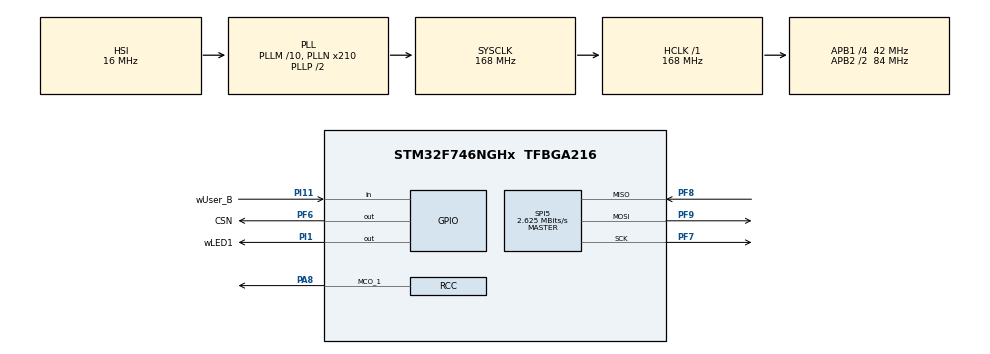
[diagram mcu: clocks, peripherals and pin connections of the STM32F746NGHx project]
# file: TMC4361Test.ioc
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Dma.Request0=SPI5_RX
Dma.Request1=SPI5_TX
Dma.SPI5_RX.0.Direction=DMA_PERIPH_TO_MEMORY
Dma.SPI5_RX.0.FIFOMode=DMA_FIFOMODE_DISABLE
Dma.SPI5_RX.0.Instance=DMA2_Stream3
Dma.SPI5_RX.0.MemDataAlignment=DMA_MDATAALIGN_BYTE
Dma.SPI5_RX.0.MemInc=DMA_MINC_ENABLE
Dma.SPI5_RX.0.Mode=DMA_CIRCULAR
Dma.SPI5_RX.0.PeriphDataAlignment=DMA_PDATAALIGN_BYTE
Dma.SPI5_RX.0.PeriphInc=DMA_PINC_DISABLE
Dma.SPI5_RX.0.Priority=DMA_PRIORITY_MEDIUM
Dma.SPI5_TX.1.Direction=DMA_MEMORY_TO_PERIPH
Dma.SPI5_TX.1.FIFOMode=DMA_FIFOMODE_DISABLE
Dma.SPI5_TX.1.Instance=DMA2_Stream4
Dma.SPI5_TX.1.MemDataAlignment=DMA_MDATAALIGN_BYTE
Dma.SPI5_TX.1.MemInc=DMA_MINC_ENABLE
Dma.SPI5_TX.1.Mode=DMA_CIRCULAR
Dma.SPI5_TX.1.PeriphDataAlignment=DMA_PDATAALIGN_BYTE
Dma.SPI5_TX.1.PeriphInc=DMA_PINC_DISABLE
Dma.SPI5_TX.1.Priority=DMA_PRIORITY_MEDIUM
Mcu.Family=STM32F7
Mcu.Name=STM32F746NGHx
Mcu.Package=TFBGA216
NVIC.DMA2_Stream3_IRQn=true\:0\:0\:false\:false\:true\:false\:true
NVIC.DMA2_Stream4_IRQn=true\:0\:0\:false\:false\:true\:false\:true
NVIC.PriorityGroup=NVIC_PRIORITYGROUP_4
NVIC.SPI5_IRQn=true\:0\:0\:false\:false\:true\:true\:true
PA8.Mode=Clock-out-1
PA8.Signal=RCC_MCO_1
PF6.GPIO_Label=CSN
PF6.Signal=GPIO_Output
PF7.Mode=Full_Duplex_Master
PF7.Signal=SPI5_SCK
PF8.Mode=Full_Duplex_Master
PF8.Signal=SPI5_MISO
PF9.Mode=Full_Duplex_Master
PF9.Signal=SPI5_MOSI
PH0/OSC_IN.Mode=HSE-External-Oscillator
PH0/OSC_IN.Signal=RCC_OSC_IN
PH1/OSC_OUT.Mode=HSE-External-Oscillator
PH1/OSC_OUT.Signal=RCC_OSC_OUT
PI1.GPIO_Label=wLED1
PI1.Signal=GPIO_Output
PI11.GPIO_Label=wUser_B
PI11.Signal=GPIO_Input
ProjectManager.HeapSize=0x200
ProjectManager.StackSize=0x400
ProjectManager.TargetToolchain=MDK-ARM V5.27
RCC.AHBFreq_Value=168000000
RCC.APB1CLKDivider=RCC_HCLK_DIV4
RCC.APB1Freq_Value=42000000
RCC.APB1TimFreq_Value=84000000
RCC.APB2CLKDivider=RCC_HCLK_DIV2
RCC.APB2Freq_Value=84000000
RCC.APB2TimFreq_Value=168000000
RCC.CortexFreq_Value=168000000
RCC.HCLKFreq_Value=168000000
RCC.HSE_VALUE=25000000
RCC.HSI_VALUE=16000000
RCC.LSE_VALUE=32768
RCC.PLLM=10
RCC.PLLN=210
RCC.PLLSourceVirtual=RCC_PLLSOURCE_HSI
RCC.SYSCLKFreq_VALUE=168000000
RCC.SYSCLKSource=RCC_SYSCLKSOURCE_PLLCLK
RCC.USBFreq_Value=168000000
RCC.VCOOutputFreq_Value=336000000
SPI5.BaudRatePrescaler=SPI_BAUDRATEPRESCALER_32
SPI5.CalculateBaudRate=2.625 MBits/s
SPI5.DataSize=SPI_DATASIZE_8BIT
SPI5.Direction=SPI_DIRECTION_2LINES
SPI5.Mode=SPI_MODE_MASTER
SPI5.NSSPMode=SPI_NSS_PULSE_DISABLE
SPI5.VirtualType=VM_MASTER
board=STM32F746G-DISCO

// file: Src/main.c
/* USER CODE BEGIN Header */
/**
  ******************************************************************************
  * @file           : main.c
  * @brief          : Main program body
  ******************************************************************************
  * @attention
  *
  * <h2><center>&copy; Copyright (c) 2020 STMicroelectronics.
  * All rights reserved.</center></h2>
  *
  * This software component is licensed by ST under BSD 3-Clause license,
  * the "License"; You may not use this file except in compliance with the
  * License. You may obtain a copy of the License at:
  *                        opensource.org/licenses/BSD-3-Clause
  *
  ******************************************************************************
  */
/* USER CODE END Header */

#include "main.h"

SPI_HandleTypeDef hspi5;
DMA_HandleTypeDef hdma_spi5_rx;
DMA_HandleTypeDef hdma_spi5_tx;

/* USER CODE BEGIN PV */
uint8_t wTxData[5];
uint8_t wRxData[5];
/* USER CODE END PV */

void SystemClock_Config(void);
static void MX_GPIO_Init(void);
static void MX_DMA_Init(void);
static void MX_SPI5_Init(void);

int main(void)
{
  /* USER CODE BEGIN 1 */
	wTxData[0]=0x0B;
	wTxData[1]=0x00;
	wTxData[2]=0x00;
	wTxData[3]=0x00;
	wTxData[4]=0x00;

  /* USER CODE END 1 */

  /* MCU Configuration--------------------------------------------------------*/

  /* Reset of all peripherals, Initializes the Flash interface and the Systick. */
  HAL_Init();

  /* Configure the system clock */
  SystemClock_Config();

  /* Initialize all configured peripherals */
  MX_GPIO_Init();
  MX_DMA_Init();
  MX_SPI5_Init();

  /* Infinite loop */
  while (1)
  {

    /* USER CODE BEGIN 3 */
		GPIOI->ODR &= ~(1UL << 1);
		HAL_SPI_Transmit(&hspi5,(uint8_t *)wTxData,5,5000);
		GPIOI->ODR |= 1UL << 1;

		HAL_Delay(1000);
  }
  /* USER CODE END 3 */
}

void SystemClock_Config(void)
{
  RCC_OscInitTypeDef RCC_OscInitStruct = {0};
  RCC_ClkInitTypeDef RCC_ClkInitStruct = {0};

  /** Configure the main internal regulator output voltage
  */
  __HAL_RCC_PWR_CLK_ENABLE();
  __HAL_PWR_VOLTAGESCALING_CONFIG(PWR_REGULATOR_VOLTAGE_SCALE2);
  /** Initializes the CPU, AHB and APB busses clocks
  */
  RCC_OscInitStruct.OscillatorType = RCC_OSCILLATORTYPE_HSI;
  RCC_OscInitStruct.HSIState = RCC_HSI_ON;
  RCC_OscInitStruct.HSICalibrationValue = RCC_HSICALIBRATION_DEFAULT;
  RCC_OscInitStruct.PLL.PLLState = RCC_PLL_ON;
  RCC_OscInitStruct.PLL.PLLSource = RCC_PLLSOURCE_HSI;
  RCC_OscInitStruct.PLL.PLLM = 10;
  RCC_OscInitStruct.PLL.PLLN = 210;
  RCC_OscInitStruct.PLL.PLLP = RCC_PLLP_DIV2;
  RCC_OscInitStruct.PLL.PLLQ = 2;
  if (HAL_RCC_OscConfig(&RCC_OscInitStruct) != HAL_OK)
  {
    Error_Handler();
  }
  /** Initializes the CPU, AHB and APB busses clocks
  */
  RCC_ClkInitStruct.ClockType = RCC_CLOCKTYPE_HCLK|RCC_CLOCKTYPE_SYSCLK
                              |RCC_CLOCKTYPE_PCLK1|RCC_CLOCKTYPE_PCLK2;
  RCC_ClkInitStruct.SYSCLKSource = RCC_SYSCLKSOURCE_PLLCLK;
  RCC_ClkInitStruct.AHBCLKDivider = RCC_SYSCLK_DIV1;
  RCC_ClkInitStruct.APB1CLKDivider = RCC_HCLK_DIV4;
  RCC_ClkInitStruct.APB2CLKDivider = RCC_HCLK_DIV2;

  if (HAL_RCC_ClockConfig(&RCC_ClkInitStruct, FLASH_LATENCY_5) != HAL_OK)
  {
    Error_Handler();
  }
  HAL_RCC_MCOConfig(RCC_MCO1, RCC_MCO1SOURCE_HSI, RCC_MCODIV_1);
}

static void MX_SPI5_Init(void)
{

  /* SPI5 parameter configuration*/
  hspi5.Instance = SPI5;
  hspi5.Init.Mode = SPI_MODE_MASTER;
  hspi5.Init.Direction = SPI_DIRECTION_2LINES;
  hspi5.Init.DataSize = SPI_DATASIZE_8BIT;
  hspi5.Init.CLKPolarity = SPI_POLARITY_LOW;
  hspi5.Init.CLKPhase = SPI_PHASE_1EDGE;
  hspi5.Init.NSS = SPI_NSS_SOFT;
  hspi5.Init.BaudRatePrescaler = SPI_BAUDRATEPRESCALER_128;
  hspi5.Init.FirstBit = SPI_FIRSTBIT_MSB;
  hspi5.Init.TIMode = SPI_TIMODE_DISABLE;
  hspi5.Init.CRCCalculation = SPI_CRCCALCULATION_DISABLE;
  hspi5.Init.CRCPolynomial = 7;
  hspi5.Init.CRCLength = SPI_CRC_LENGTH_DATASIZE;
  hspi5.Init.NSSPMode = SPI_NSS_PULSE_DISABLE;
  if (HAL_SPI_Init(&hspi5) != HAL_OK)
  {
    Error_Handler();
  }
  /* USER CODE BEGIN SPI5_Init 2 */
		GPIOI->ODR |= 1UL << 1;

  /* USER CODE END SPI5_Init 2 */

}

static void MX_DMA_Init(void)
{

  /* DMA controller clock enable */
  __HAL_RCC_DMA2_CLK_ENABLE();

  /* DMA interrupt init */
  /* DMA2_Stream3_IRQn interrupt configuration */
  HAL_NVIC_SetPriority(DMA2_Stream3_IRQn, 0, 0);
  HAL_NVIC_EnableIRQ(DMA2_Stream3_IRQn);
  /* DMA2_Stream4_IRQn interrupt configuration */
  HAL_NVIC_SetPriority(DMA2_Stream4_IRQn, 0, 0);
  HAL_NVIC_EnableIRQ(DMA2_Stream4_IRQn);

}

static void MX_GPIO_Init(void)
{
  GPIO_InitTypeDef GPIO_InitStruct = {0};

  /* GPIO Ports Clock Enable */
  __HAL_RCC_GPIOI_CLK_ENABLE();
  __HAL_RCC_GPIOA_CLK_ENABLE();
  __HAL_RCC_GPIOH_CLK_ENABLE();
  __HAL_RCC_GPIOF_CLK_ENABLE();

  /*Configure GPIO pin Output Level */
  HAL_GPIO_WritePin(wLED1_GPIO_Port, wLED1_Pin, GPIO_PIN_RESET);

  /*Configure GPIO pin Output Level */
  HAL_GPIO_WritePin(CSN_GPIO_Port, CSN_Pin, GPIO_PIN_RESET);

  /*Configure GPIO pin : wLED1_Pin */
  GPIO_InitStruct.Pin = wLED1_Pin;
  GPIO_InitStruct.Mode = GPIO_MODE_OUTPUT_PP;
  GPIO_InitStruct.Pull = GPIO_NOPULL;
  GPIO_InitStruct.Speed = GPIO_SPEED_FREQ_LOW;
  HAL_GPIO_Init(wLED1_GPIO_Port, &GPIO_InitStruct);

  /*Configure GPIO pin : wUser_B_Pin */
  GPIO_InitStruct.Pin = wUser_B_Pin;
  GPIO_InitStruct.Mode = GPIO_MODE_INPUT;
  GPIO_InitStruct.Pull = GPIO_NOPULL;
  HAL_GPIO_Init(wUser_B_GPIO_Port, &GPIO_InitStruct);

  /*Configure GPIO pin : PA8 */
  GPIO_InitStruct.Pin = GPIO_PIN_8;
  GPIO_InitStruct.Mode = GPIO_MODE_AF_PP;
  GPIO_InitStruct.Pull = GPIO_NOPULL;
  GPIO_InitStruct.Speed = GPIO_SPEED_FREQ_LOW;
  GPIO_InitStruct.Alternate = GPIO_AF0_MCO;
  HAL_GPIO_Init(GPIOA, &GPIO_InitStruct);

  /*Configure GPIO pin : CSN_Pin */
  GPIO_InitStruct.Pin = CSN_Pin;
  GPIO_InitStruct.Mode = GPIO_MODE_OUTPUT_PP;
  GPIO_InitStruct.Pull = GPIO_NOPULL;
  GPIO_InitStruct.Speed = GPIO_SPEED_FREQ_LOW;
  HAL_GPIO_Init(CSN_GPIO_Port, &GPIO_InitStruct);

}

void Error_Handler(void)
{
}

/************************ (C) COPYRIGHT STMicroelectronics *****END OF FILE****/
